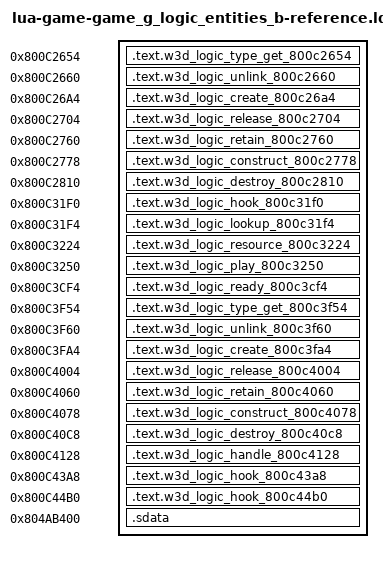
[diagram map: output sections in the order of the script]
/* Generated reference-only placements. All bodies are source-built. */
OUTPUT_FORMAT("elf32-powerpc")
OUTPUT_ARCH(powerpc)
ENTRY(w3d_logic_type_get_800c2654)
_SDA_BASE_ = 0x804b2540;
_SDA2_BASE_ = 0x804c2540;
w3d_actor_base_destroy = 0x80161050;
w3d_actor_base_initialize = 0x80161014;
w3d_actor_handle_8015fb34 = 0x8015fb34;
w3d_actor_handle_member_destroy = 0x80126230;
w3d_actor_lookup_80164fc8 = 0x80164fc8;
w3d_base_construct_8015fef0 = 0x8015fef0;
w3d_base_destroy_8015ff2c = 0x8015ff2c;
w3d_class_8040fb28 = 0x8040fb28;
w3d_class_80410680 = 0x80410680;
w3d_class_create_8020b680 = 0x8020b680;
w3d_constructor_lookup_name = 0x800fc1b0;
w3d_empty_80341584 = 0x80341584;
w3d_empty_803426b4 = 0x803426b4;
w3d_f32_80383248 = 0x80383248;
w3d_f32_8038346c = 0x8038346c;
w3d_f32_8038356c = 0x8038356c;
w3d_fn_800fc6dc = 0x800fc6dc;
w3d_fn_80178c48 = 0x80178c48;
w3d_handle_storage_release = 0x802134fc;
w3d_heap_allocate_entry_a = 0x801fe1d8;
w3d_logic_type_80360a20 = 0x80360a20;
w3d_logic_type_80360a50 = 0x80360a50;
w3d_lookup_text_800fc550 = 0x800fc550;
w3d_owner_list_remove = 0x8020fd2c;
w3d_registry_add_80164514 = 0x80164514;
w3d_set_float_800fc4c8 = 0x800fc4c8;
w3d_spawn_effect_800e5ca4 = 0x800e5ca4;
w3d_state_register = 0x8020fd04;
w3d_str_80383470 = 0x80383470;
w3d_str_8038349c = 0x8038349c;
w3d_str_803834b0 = 0x803834b0;
w3d_str_803834c0 = 0x803834c0;
w3d_str_803834d0 = 0x803834d0;
w3d_str_803834dc = 0x803834dc;
w3d_str_803834f0 = 0x803834f0;
w3d_str_80383504 = 0x80383504;
w3d_str_80383520 = 0x80383520;
w3d_str_80383538 = 0x80383538;
w3d_str_80383554 = 0x80383554;
w3d_target_id_80156f88 = 0x80156f88;
w3d_timed_lookup_801797b4 = 0x801797b4;
w3d_vtable_8040f9a8 = 0x8040f9a8;
w3d_vtable_8040f9e8 = 0x8040f9e8;
SECTIONS {
  .text.w3d_logic_type_get_800c2654 0x800c2654 : { *(.text.w3d_logic_type_get_800c2654) }
  .text.w3d_logic_unlink_800c2660 0x800c2660 : { *(.text.w3d_logic_unlink_800c2660) }
  .text.w3d_logic_create_800c26a4 0x800c26a4 : { *(.text.w3d_logic_create_800c26a4) }
  .text.w3d_logic_release_800c2704 0x800c2704 : { *(.text.w3d_logic_release_800c2704) }
  .text.w3d_logic_retain_800c2760 0x800c2760 : { *(.text.w3d_logic_retain_800c2760) }
  .text.w3d_logic_construct_800c2778 0x800c2778 : { *(.text.w3d_logic_construct_800c2778) }
  .text.w3d_logic_destroy_800c2810 0x800c2810 : { *(.text.w3d_logic_destroy_800c2810) }
  .text.w3d_logic_hook_800c31f0 0x800c31f0 : { *(.text.w3d_logic_hook_800c31f0) }
  .text.w3d_logic_lookup_800c31f4 0x800c31f4 : { *(.text.w3d_logic_lookup_800c31f4) }
  .text.w3d_logic_resource_800c3224 0x800c3224 : { *(.text.w3d_logic_resource_800c3224) }
  .text.w3d_logic_play_800c3250 0x800c3250 : { *(.text.w3d_logic_play_800c3250) }
  .text.w3d_logic_ready_800c3cf4 0x800c3cf4 : { *(.text.w3d_logic_ready_800c3cf4) }
  .text.w3d_logic_type_get_800c3f54 0x800c3f54 : { *(.text.w3d_logic_type_get_800c3f54) }
  .text.w3d_logic_unlink_800c3f60 0x800c3f60 : { *(.text.w3d_logic_unlink_800c3f60) }
  .text.w3d_logic_create_800c3fa4 0x800c3fa4 : { *(.text.w3d_logic_create_800c3fa4) }
  .text.w3d_logic_release_800c4004 0x800c4004 : { *(.text.w3d_logic_release_800c4004) }
  .text.w3d_logic_retain_800c4060 0x800c4060 : { *(.text.w3d_logic_retain_800c4060) }
  .text.w3d_logic_construct_800c4078 0x800c4078 : { *(.text.w3d_logic_construct_800c4078) }
  .text.w3d_logic_destroy_800c40c8 0x800c40c8 : { *(.text.w3d_logic_destroy_800c40c8) }
  .text.w3d_logic_handle_800c4128 0x800c4128 : { *(.text.w3d_logic_handle_800c4128) }
  .text.w3d_logic_hook_800c43a8 0x800c43a8 : { *(.text.w3d_logic_hook_800c43a8) }
  .text.w3d_logic_hook_800c44b0 0x800c44b0 : { *(.text.w3d_logic_hook_800c44b0) }
  .sdata 0x804ab400 (NOLOAD) : {
    . = 0x0; w3d_target_source_804ab400 = .;
    . = 0x6388; w3d_game_804b1788 = .;
    . = 0x638c; w3d_registry_804b178c = .;
    . += 1; }
  /DISCARD/ : { *(.text*) *(.rodata*) *(.data*) *(.bss*) *(.sdata*) *(.sbss*) *(.comment) }
}
